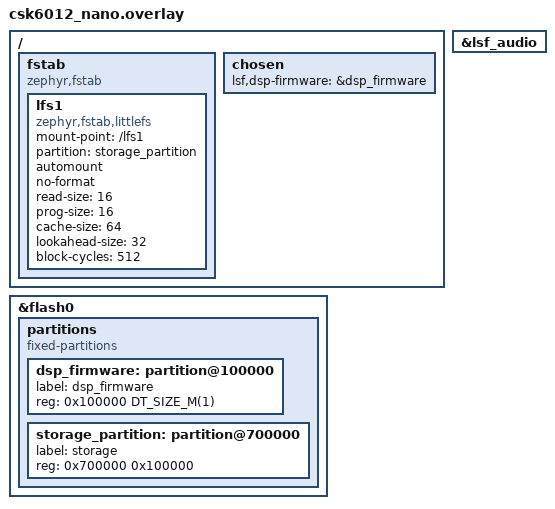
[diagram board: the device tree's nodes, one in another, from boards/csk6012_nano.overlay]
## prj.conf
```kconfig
#
# Copyright (c) 2019 Peter Bigot Consulting, LLC
#
# SPDX-License-Identifier: Apache-2.0
#

# Optionally force the file system to be recreated
#CONFIG_APP_WIPE_STORAGE=y

# fs_dirent structures are big.
CONFIG_MAIN_STACK_SIZE=2048

# Let __ASSERT do its job
CONFIG_DEBUG=y

CONFIG_LOG=y
CONFIG_LOG_MODE_MINIMAL=y

CONFIG_FLASH=y
CONFIG_FLASH_MAP=y
CONFIG_FLASH_PAGE_LAYOUT=y

CONFIG_FILE_SYSTEM=y
CONFIG_FILE_SYSTEM_LITTLEFS=y

CONFIG_MASS_STORAGE_DISK_NAME="lfs1"
#USB related configs
CONFIG_USB_DEVICE_STACK=y
CONFIG_USB_DEVICE_PRODUCT="Zephyr MSC sample"
CONFIG_USB_DRIVER_LOG_LEVEL_ERR=y
CONFIG_USB_MASS_STORAGE=y
CONFIG_USB_DEVICE_LOG_LEVEL_ERR=y
CONFIG_USB_MASS_STORAGE_LOG_LEVEL_ERR=y

CONFIG_MASS_STORAGE_STACK_SIZE=2048

CONFIG_HEAP_MEM_POOL_SIZE=204800

CONFIG_CSK_HEAP=y
CONFIG_CSK_HEAP_MEM_POOL_SIZE=40960

CONFIG_CSK6_FLASH_STALL_SECOND_CORE=n
```

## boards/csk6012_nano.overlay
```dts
/*
 * Copyright (c) 2020 Circuit Dojo LLC
 *
 * SPDX-License-Identifier: Apache-2.0
 */

#include <lsf/lsf.dtsi>

/delete-node/ &storage_partition;

/ {
	fstab {
		compatible = "zephyr,fstab";
		lfs1: lfs1 {
			compatible = "zephyr,fstab,littlefs";
			mount-point = "/lfs1";
			partition = <&storage_partition>;
			automount ;
			no-format;
			read-size = <16>;
			prog-size = <16>;
			cache-size = <64>;
			lookahead-size = <32>;
			block-cycles = <512>;
		};
	};

};

/ {
        chosen {
                lsf,dsp-firmware = &dsp_firmware;
        };
};
 
&flash0 {
	partitions {
		compatible = "fixed-partitions";
		#address-cells = <1>;
		#size-cells = <1>;

		dsp_firmware: partition@100000 {
			label = "dsp_firmware";
			reg = <0x100000 DT_SIZE_M(1)>;
		};

		/* storage: 1MB for storage */
		storage_partition: partition@700000 {
			label = "storage";
			reg = <0x700000 0x100000>;
		};

	};
};

&lsf_audio {
	status = "okay";
};
```

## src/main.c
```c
/*
 * Copyright (c) 2022 Lukasz Majewski, DENX Software Engineering GmbH
 * Copyright (c) 2019 Peter Bigot Consulting, LLC
 *
 * SPDX-License-Identifier: Apache-2.0
 */

/* Sample which uses the filesystem API with littlefs */

#include <stdio.h>

#include <zephyr/zephyr.h>
#include <zephyr/device.h>
#include <zephyr/fs/fs.h>
#include <zephyr/fs/littlefs.h>
#include <zephyr/logging/log.h>
#include <zephyr/storage/flash_map.h>


#include "AudioSystem.h"
#include "AudioTrack.h"
#include "AudioRecord.h"
#include "Errors.h"

#define SAMPLE_RATE (16000)
#define CHANNEL_CNT (1)

#define RECORD_SECS       (5)
#define RECORD_SAMPLE_CNT (SAMPLE_RATE * RECORD_SECS)

#define MAX_PATH_LEN 255

static AudioRecord s_record_obj;
static AudioTrack s_track_obj;

__attribute__((section(".psram_section"))) static uint8_t
	recording[sizeof(uint16_t) * RECORD_SAMPLE_CNT * CHANNEL_CNT];

LOG_MODULE_REGISTER(main);

/* Matches LFS_NAME_MAX */
#define MAX_PATH_LEN 255
#define TEST_FILE_SIZE 547

static uint8_t file_test_pattern[TEST_FILE_SIZE];
static int lsdir(const char *path)
{
	int res;
	struct fs_dir_t dirp;
	static struct fs_dirent entry;

	fs_dir_t_init(&dirp);

	/* Verify fs_opendir() */
	res = fs_opendir(&dirp, path);
	if (res) {
		LOG_ERR("Error opening dir %s [%d]\n", path, res);
		return res;
	}

	LOG_PRINTK("\nListing dir %s ...\n", path);
	for (;;) {
		/* Verify fs_readdir() */
		res = fs_readdir(&dirp, &entry);

		/* entry.name[0] == 0 means end-of-dir */
		if (res || entry.name[0] == 0) {
			if (res < 0) {
				LOG_ERR("Error reading dir [%d]\n", res);
			}
			break;
		}

		if (entry.type == FS_DIR_ENTRY_DIR) {
			LOG_PRINTK("[DIR ] %s\n", entry.name);
		} else {
			LOG_PRINTK("[FILE] %s (size = %zu)\n",
				   entry.name, entry.size);
		}
	}

	/* Verify fs_closedir() */
	fs_closedir(&dirp);

	return res;
}

static int littlefs_increase_infile_value(char *fname)
{
	uint8_t boot_count = 0;
	struct fs_file_t file;
	int rc, ret;

	AudioTrack *track = &s_track_obj;
	AudioRecord *record = &s_record_obj;

	fs_file_t_init(&file);
	rc = fs_open(&file, fname, FS_O_CREATE | FS_O_RDWR);
	if (rc < 0) {
		LOG_ERR("FAIL: open %s: %d", log_strdup(fname), rc);
		return rc;
	}

	rc = fs_read(&file, &boot_count, sizeof(boot_count));
	if (rc < 0) {
		LOG_ERR("FAIL: read %s: [rd:%d]", log_strdup(fname), rc);
		goto out;
	}
	LOG_PRINTK("%s read count:%u (bytes: %d)\n", fname, boot_count, rc);

	rc = fs_seek(&file, 0, FS_SEEK_SET);
	if (rc < 0) {
		LOG_ERR("FAIL: seek %s: %d", log_strdup(fname), rc);
		goto out;
	}

	LOG_PRINTK("before audio record ctor\n");
	ret = AudioRecord_ctor(record, 0, SAMPLE_RATE, PCM_16_BIT, CHANNEL_IN_LEFT, 160, NULL);

	LOG_PRINTK("before audio track ctor\n");
	ret = AudioTrack_ctor(track, SAMPLE_RATE, PCM_16_BIT, CHANNEL_OUT_MONO, 160, NULL);
	
	for (int i=1;i<=4;i++)
	{
		LOG_PRINTK("loop %d\n", i);
		AudioRecord_start(record);
		
		ret = AudioRecord_read(record, recording,
						sizeof(uint16_t) * RECORD_SAMPLE_CNT * CHANNEL_CNT);

		AudioTrack_start(track);
		
		ret = AudioTrack_write(track, recording,
						sizeof(uint16_t) * RECORD_SAMPLE_CNT * CHANNEL_CNT);

		LOG_PRINTK("save voice\n");
		int save_bytes = fs_write(&file, recording, sizeof(uint16_t) * RECORD_SAMPLE_CNT * CHANNEL_CNT);
		if (save_bytes < 0)
		{		
			LOG_ERR("FAIL: write %s: %d", log_strdup(fname), rc);
			goto out;	
		}
		else
		{
			LOG_PRINTK("voice file save ok,=%d\n", save_bytes);
		}
	}

	
	ret = AudioTrack_dtor(track);
	ret = AudioRecord_dtor(record);

 out:
	ret = fs_close(&file);
	if (ret < 0) {
		LOG_ERR("FAIL: close %s: %d", log_strdup(fname), ret);
		return ret;
	}

	return (rc < 0 ? rc : 0);
}

static void incr_pattern(uint8_t *p, uint16_t size, uint8_t inc)
{
	uint8_t fill = 0x55;

	if (p[0] % 2 == 0) {
		fill = 0xAA;
	}

	for (int i = 0; i < (size - 1); i++) {
		if (i % 8 == 0) {
			p[i] += inc;
		} else {
			p[i] = fill;
		}
	}

	p[size - 1] += inc;
}

static void init_pattern(uint8_t *p, uint16_t size)
{
	uint8_t v = 0x1;

	memset(p, 0x55, size);

	for (int i = 0; i < size; i += 8) {
		p[i] = v++;
	}

	p[size - 1] = 0xAA;
}

static void print_pattern(uint8_t *p, uint16_t size)
{
	int i, j = size / 16, k;

	for (k = 0, i = 0; k < j; i += 16, k++) {
		LOG_PRINTK("%02x %02x %02x %02x %02x %02x %02x %02x ",
			   p[i], p[i+1], p[i+2], p[i+3],
			   p[i+4], p[i+5], p[i+6], p[i+7]);
		LOG_PRINTK("%02x %02x %02x %02x %02x %02x %02x %02x\n",
			   p[i+8], p[i+9], p[i+10], p[i+11],
			   p[i+12], p[i+13], p[i+14], p[i+15]);

		/* Mark 512B (sector) chunks of the test file */
		if ((k + 1) % 32 == 0) {
			LOG_PRINTK("\n");
		}
	}

	for (; i < size; i++) {
		LOG_PRINTK("%02x ", p[i]);
	}

	LOG_PRINTK("\n");
}

static int littlefs_binary_file_adj(char *fname)
{
	struct fs_dirent dirent;
	struct fs_file_t file;
	int rc, ret;

	/*
	 * Uncomment below line to force re-creation of the test pattern
	 * file on the littlefs FS.
	 */
	/* fs_unlink(fname); */
	fs_file_t_init(&file);

	rc = fs_open(&file, fname, FS_O_CREATE | FS_O_RDWR);
	if (rc < 0) {
		LOG_ERR("FAIL: open %s: %d", log_strdup(fname), rc);
		return rc;
	}

	rc = fs_stat(fname, &dirent);
	if (rc < 0) {
		LOG_ERR("FAIL: stat %s: %d", log_strdup(fname), rc);
		goto out;
	}

	/* Check if the file exists - if not just write the pattern */
	if (rc == 0 && dirent.type == FS_DIR_ENTRY_FILE && dirent.size == 0) {
		LOG_INF("Test file: %s not found, create one!",
			log_strdup(fname));
		init_pattern(file_test_pattern, sizeof(file_test_pattern));
	} else {
		rc = fs_read(&file, file_test_pattern,
			     sizeof(file_test_pattern));
		if (rc < 0) {
			LOG_ERR("FAIL: read %s: [rd:%d]",
				log_strdup(fname), rc);
			goto out;
		}
		incr_pattern(file_test_pattern, sizeof(file_test_pattern), 0x1);
	}

	LOG_PRINTK("------ FILE: %s ------\n", fname);
	print_pattern(file_test_pattern, sizeof(file_test_pattern));

	rc = fs_seek(&file, 0, FS_SEEK_SET);
	if (rc < 0) {
		LOG_ERR("FAIL: seek %s: %d", log_strdup(fname), rc);
		goto out;
	}

	rc = fs_write(&file, file_test_pattern, sizeof(file_test_pattern));
	if (rc < 0) {
		LOG_ERR("FAIL: write %s: %d", log_strdup(fname), rc);
	}

 out:
	ret = fs_close(&file);
	if (ret < 0) {
		LOG_ERR("FAIL: close %s: %d", log_strdup(fname), ret);
		return ret;
	}

	return (rc < 0 ? rc : 0);
}

#ifdef CONFIG_APP_LITTLEFS_STORAGE_FLASH
static int littlefs_flash_erase(unsigned int id)
{
	const struct flash_area *pfa;
	int rc;

	rc = flash_area_open(id, &pfa);
	if (rc < 0) {
		LOG_ERR("FAIL: unable to find flash area %u: %d\n",
			id, rc);
		return rc;
	}

	LOG_PRINTK("Area %u at 0x%x on %s for %u bytes\n",
		   id, (unsigned int)pfa->fa_off, pfa->fa_dev_name,
		   (unsigned int)pfa->fa_size);

	/* Optional wipe flash contents */
	if (IS_ENABLED(CONFIG_APP_WIPE_STORAGE)) {
		rc = flash_area_erase(pfa, 0, pfa->fa_size);
		LOG_ERR("Erasing flash area ... %d", rc);
	}

	flash_area_close(pfa);
	return rc;
}
#define PARTITION_NODE DT_NODELABEL(lfs1)

#if DT_NODE_EXISTS(PARTITION_NODE)
FS_FSTAB_DECLARE_ENTRY(PARTITION_NODE);
#else /* PARTITION_NODE */
FS_LITTLEFS_DECLARE_DEFAULT_CONFIG(storage);
static struct fs_mount_t lfs_storage_mnt = {
	.type = FS_LITTLEFS,
	.fs_data = &storage,
	.storage_dev = (void *)FLASH_AREA_ID(storage),
	.mnt_point = "/lfs",
};
#endif /* PARTITION_NODE */

	struct fs_mount_t *mp =
#if DT_NODE_EXISTS(PARTITION_NODE)
		&FS_FSTAB_ENTRY(PARTITION_NODE)
#else
		&lfs_storage_mnt
#endif
		;

static int littlefs_mount(struct fs_mount_t *mp)
{
	int rc;

	rc = littlefs_flash_erase((uintptr_t)mp->storage_dev);
	if (rc < 0) {
		return rc;
	}

	/* Do not mount if auto-mount has been enabled */
#if !DT_NODE_EXISTS(PARTITION_NODE) ||						\
	!(FSTAB_ENTRY_DT_MOUNT_FLAGS(PARTITION_NODE) & FS_MOUNT_FLAG_AUTOMOUNT)
	rc = fs_mount(mp);
	if (rc < 0) {
		LOG_PRINTK("FAIL: mount id %" PRIuPTR " at %s: %d\n",
		       (uintptr_t)mp->storage_dev, mp->mnt_point, rc);
		return rc;
	}
	LOG_PRINTK("%s mount: %d\n", mp->mnt_point, rc);
#else
	LOG_PRINTK("%s automounted\n", mp->mnt_point);
#endif

	return 0;
}
#endif /* CONFIG_APP_LITTLEFS_STORAGE_FLASH */

#ifdef CONFIG_APP_LITTLEFS_STORAGE_BLK_SDMMC
struct fs_littlefs lfsfs;
static struct fs_mount_t __mp = {
	.type = FS_LITTLEFS,
	.fs_data = &lfsfs,
	.flags = FS_MOUNT_FLAG_USE_DISK_ACCESS,
};
struct fs_mount_t *mp = &__mp;

static int littlefs_mount(struct fs_mount_t *mp)
{
	static const char *disk_mount_pt = "/"CONFIG_SDMMC_VOLUME_NAME":";
	static const char *disk_pdrv = CONFIG_SDMMC_VOLUME_NAME;

	mp->storage_dev = (void *)disk_pdrv;
	mp->mnt_point = disk_mount_pt;

	return fs_mount(mp);
}
#endif /* CONFIG_APP_LITTLEFS_STORAGE_BLK_SDMMC */

void main(void)
{
	int ret = 0;
	char fname1[MAX_PATH_LEN];
	char fname2[MAX_PATH_LEN];
	struct fs_statvfs sbuf;
	int rc;

	LOG_PRINTK("Sample program to r/w files on littlefs\n");

	rc = littlefs_mount(mp);
	if (rc < 0) {
		return;
	}

	snprintf(fname1, sizeof(fname1), "%s/boot_count", mp->mnt_point);
	snprintf(fname2, sizeof(fname2), "%s/pattern.bin", mp->mnt_point);

	rc = fs_statvfs(mp->mnt_point, &sbuf);
	if (rc < 0) {
		LOG_PRINTK("FAIL: statvfs: %d\n", rc);
		goto out;
	}

	LOG_PRINTK("%s: bsize = %lu ; frsize = %lu ;"
		   " blocks = %lu ; bfree = %lu\n",
		   mp->mnt_point,
		   sbuf.f_bsize, sbuf.f_frsize,
		   sbuf.f_blocks, sbuf.f_bfree);

	rc = lsdir(mp->mnt_point);
	if (rc < 0) {
		LOG_PRINTK("FAIL: lsdir %s: %d\n", mp->mnt_point, rc);
		goto out;
	}

	rc = littlefs_increase_infile_value(fname1);
	if (rc) {
		goto out;
	}

	// rc = littlefs_binary_file_adj(fname2);
	// if (rc) {
	// 	goto out;
	// }
	
	ret = usb_enable(NULL);
	if (ret != 0) {
		LOG_ERR("Failed to enable USB");
		return;
	}

	LOG_INF("The device is put in USB mass storage mode.\n");

out:
	rc = fs_unmount(mp);
	LOG_PRINTK("%s unmount: %d\n", mp->mnt_point, rc);
}
```
